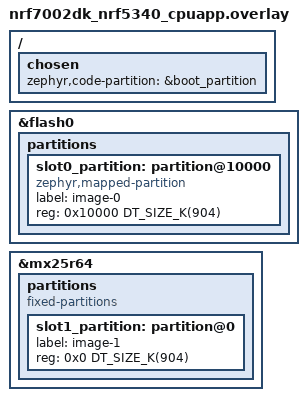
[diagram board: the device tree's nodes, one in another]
/*
 * Copyright (c) 2026 Nordic Semiconductor ASA
 *
 * SPDX-License-Identifier: LicenseRef-Nordic-5-Clause
 */

/delete-node/ &slot1_partition;

/* Shared slot0/slot1 addresses and sizes */

&flash0 {
	partitions {
		slot0_partition: partition@10000 {
			compatible = "zephyr,mapped-partition";
			label = "image-0";
			reg = <0x10000 DT_SIZE_K(904)>;
		};
	};
};

&mx25r64 {
	partitions {
		compatible = "fixed-partitions";
		#address-cells = <1>;
		#size-cells = <1>;

		slot1_partition: partition@0 {
			label = "image-1";
			reg = <0x0 DT_SIZE_K(904)>;
		};
	};
};

/ {
	chosen {
		zephyr,code-partition = &boot_partition;
	};
};
